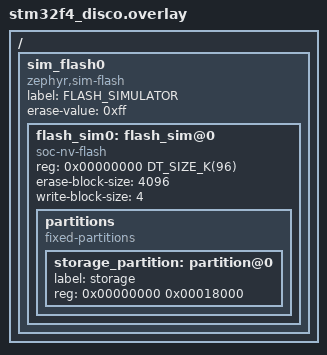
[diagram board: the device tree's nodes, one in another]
/*
 * Copyright (c) 2021 Nordic Semiconductor ASA
 *
 * SPDX-License-Identifier: Apache-2.0
 */

/ {
	sim_flash0 {
		compatible = "zephyr,sim-flash";
		label = "FLASH_SIMULATOR";

		#address-cells = <1>;
		#size-cells = <1>;
		erase-value = <0xff>;

		flash_sim0: flash_sim@0 {
			compatible = "soc-nv-flash";
			reg = <0x00000000 DT_SIZE_K(96)>;

			erase-block-size = <4096>;
			write-block-size = <4>;
		};
	};
};

&flash_sim0 {

	partitions {
		compatible = "fixed-partitions";
		#address-cells = <1>;
		#size-cells = <1>;

		storage_partition: partition@0 {
			label = "storage";
			reg = <0x00000000 0x00018000>;
		};
	};
};
